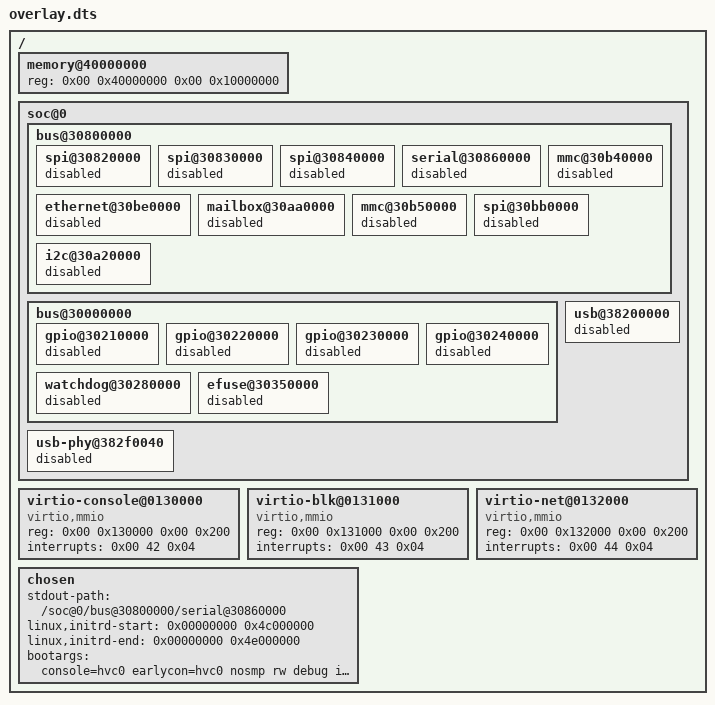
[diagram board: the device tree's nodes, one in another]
/*
 * Copyright 2024, UNSW
 *
 * SPDX-License-Identifier: BSD-2-Clause
 */
/ {
    memory@40000000 {
        device_type = "memory";
        reg = <0x00 0x40000000 0x00 0x10000000>;
    };

    soc@0 {
        bus@30800000 {
            spi@30820000 {
                status = "disabled";
            };

            spi@30830000 {
                status = "disabled";
            };

            spi@30840000 {
                status = "disabled";
            };

            serial@30860000 {
                status = "disabled";
            };

            ethernet@30be0000 {
                status = "disabled";
            };

            mailbox@30aa0000 {
                status = "disabled";
            };

            mmc@30b40000 {
                status = "disabled";
            };

            mmc@30b50000 {
                status = "disabled";
            };

            spi@30bb0000 {
                status = "disabled";
            };

            i2c@30a20000 {
                status = "disabled";
            };
        };

        bus@30000000 {
            gpio@30210000 {
                status = "disabled";
            };

            gpio@30220000 {
                status = "disabled";
            };

            gpio@30230000 {
                status = "disabled";
            };

            gpio@30240000 {
                status = "disabled";
            };

            watchdog@30280000 {
                status = "disabled";
            };

            efuse@30350000 {
                status = "disabled";
            };
        };

        usb@38200000 {
            status = "disabled";
        };

        usb-phy@382f0040 {
            status = "disabled";
        };
    };

    virtio-console@0130000 {
        compatible = "virtio,mmio";
        reg = <0x00 0x130000 0x00 0x200>;
        interrupts = <0x00 42 0x04>;
    };

    virtio-blk@0131000 {
        compatible = "virtio,mmio";
        reg = <0x00 0x131000 0x00 0x200>;
        interrupts = <0x00 43 0x04>;
    };

    virtio-net@0132000 {
        compatible = "virtio,mmio";
        reg = <0x00 0x132000 0x00 0x200>;
        interrupts = <0x00 44 0x04>;
    };


    chosen {
        stdout-path = "/soc@0/bus@30800000/serial@30860000";
        linux,initrd-start = <0x00000000 0x4c000000>;
        linux,initrd-end = <0x00000000 0x4e000000>;
        bootargs = "console=hvc0 earlycon=hvc0 nosmp rw debug ignore_loglevel initcall_blacklist=imx8_soc_init pci=nomsi earlyprintk=serial maxcpus=1";
    };
};
